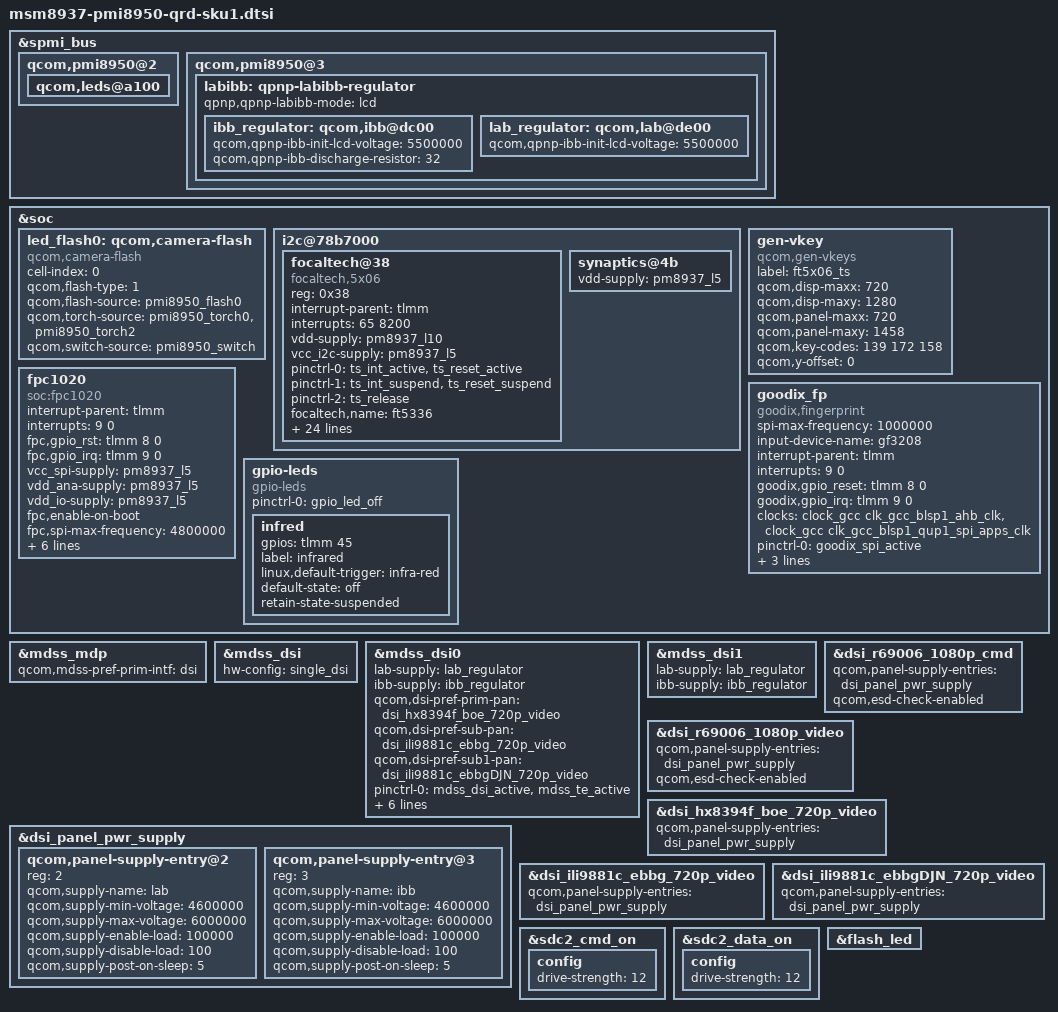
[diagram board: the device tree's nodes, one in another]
/*
 * Copyright (c) 2015-2016, The Linux Foundation. All rights reserved.
 *
 * This program is free software; you can redistribute it and/or modify
 * it under the terms of the GNU General Public License version 2 and
 * only version 2 as published by the Free Software Foundation.
 *
 * This program is distributed in the hope that it will be useful,
 * but WITHOUT ANY WARRANTY; without even the implied warranty of
 * MERCHANTABILITY or FITNESS FOR A PARTICULAR PURPOSE.  See the
 * GNU General Public License for more details.
 */

#include "msm-pmi8950.dtsi"
#include "msm8937-qrd.dtsi"
#include "msm8937-mdss-panels.dtsi"

&spmi_bus {
	qcom,pmi8950@2 {
		qcom,leds@a100 {
			//status = "okay";
			/*qcom,led_mpp_2 {
				label = "mpp";
				linux,name = "green";
				linux,default-trigger = "none";
				qcom,default-state = "off";
				qcom,max-current = <40>;
				qcom,current-setting = <5>;
				qcom,id = <6>;
				qcom,mode = "manual";
				qcom,source-sel = <1>;
				qcom,mode-ctrl = <0x60>;
			};*/
		};
	};
};

&soc {
	led_flash0: qcom,camera-flash {
		cell-index = <0>;
		compatible = "qcom,camera-flash";
		qcom,flash-type = <1>;
		qcom,flash-source = <&pmi8950_flash0>;
		qcom,torch-source = <&pmi8950_torch0 &pmi8950_torch2>;
		qcom,switch-source = <&pmi8950_switch>;
	};

	i2c@78b7000 {
		status = "ok";
		focaltech@38 {
			compatible = "focaltech,5x06"; //Our tp is FT5336
			reg = <0x38>; // 38
			interrupt-parent = <&tlmm>; // a7
			interrupts = <65 8200>;
			vdd-supply = <&pm8937_l10>; // cd
			vcc_i2c-supply = <&pm8937_l5>; //b6
			pinctrl-names = "pmx_ts_active", "pmx_ts_suspend", "pmx_ts_release";
			pinctrl-0 = <&ts_int_active &ts_reset_active>; // d0 d1
			pinctrl-1 = <&ts_int_suspend &ts_reset_suspend>; // d2 d3
			pinctrl-2 = <&ts_release>; // d4
			focaltech,name = "ft5336";
			focaltech,family-id = <0x36>;
			focaltech,reset-gpio = <&tlmm 64 0>; //a7
			focaltech,irq-gpio = <&tlmm 65 8200>; //a7
			focaltech,display-coords = <0 0 720 1280>;
			focaltech,panel-coords = <0 0 720 1280>;
			focaltech,virtual-key1 = <139 140 2000>; //menu
			focaltech,virtual-key2 = <172 360 2000>; //home
			focaltech,virtual-key3 = <158 580 2000>; //back
			//focaltech,fw-vkey-support;
			focaltech,button-map = <139 172 158>;			
			focaltech,no-force-update;
			focaltech,i2c-pull-up;
			focaltech,group-id = <1>;
			focaltech,hard-reset-delay-ms = <20>;
			focaltech,soft-reset-delay-ms = <200>;
			focaltech,num-max-touches = <10>;
			focaltech,fw-delay-aa-ms = <30>;
			focaltech,fw-delay-55-ms = <30>;
			focaltech,fw-upgrade-id1 = <121>;
			focaltech,fw-upgrade-id2 = <24>;
			focaltech,fw-delay-readid-ms = <10>;
			focaltech,fw-delay-era-flsh-ms = <2000>;
			focaltech,fw-auto-cal;
			focaltech,ignore-id-check;
			focaltech,resume-in-workqueue;
		};
		synaptics@4b {
			/*compatible = "synaptics,dsx";
			reg = <0x4b>;
			interrupt-parent = <&tlmm>;
			interrupts = <65 0x2008>;*/
			vdd-supply = <&pm8937_l5>;
			/*avdd-supply = <&pm8937_l10>;
			pinctrl-names = "pmx_ts_active","pmx_ts_suspend",
				"pmx_ts_release";
			pinctrl-0 = <&ts_int_active &ts_reset_active>;
			pinctrl-1 = <&ts_int_suspend &ts_reset_suspend>;
			pinctrl-2 = <&ts_release>;
			synaptics,display-coords = <0 0 1079 1919>;
			synaptics,panel-coords = <0 0 1079 1919>;
			synaptics,reset-gpio = <&tlmm 64 0x00>;
			synaptics,irq-gpio = <&tlmm 65 0x2008>;
			synaptics,disable-gpios;
			synaptics,button-map = <158 139 172>;
			synaptics,resume-in-workqueue;*/
			/* Underlying clocks used by secure touch */
			/*clock-names = "iface_clk", "core_clk";
			clocks = <&clock_gcc clk_gcc_blsp1_ahb_clk>,
				<&clock_gcc clk_gcc_blsp1_qup3_i2c_apps_clk>;*/
		};
	};

	gen-vkey {
			compatible = "qcom,gen-vkeys";
			label = "ft5x06_ts";
			qcom,disp-maxx = <720>; //<0x2d0>;
			qcom,disp-maxy = <1280>; //<0x500>;
			qcom,panel-maxx = <720>; //<0x2d0>;
			qcom,panel-maxy = <1458>; //<0x5b2>;
			qcom,key-codes = <139 172 158>; //<0x8b 0xac 0x9e>;
			qcom,y-offset = <0>; //<0x0>;
	};		

	//TODO Get correct gpios.
	fpc1020 {
		compatible = "soc:fpc1020";
		interrupt-parent = <&tlmm>;
		interrupts = <9 0>;
		fpc,gpio_rst = <&tlmm 8 0>;
		fpc,gpio_irq = <&tlmm 9 0>;
		vcc_spi-supply = <&pm8937_l5>;
		vdd_ana-supply = <&pm8937_l5>;
		vdd_io-supply = <&pm8937_l5>;
		fpc,enable-on-boot;
		/delete-property/
		fpc,enable-wakeup;
		fpc,spi-max-frequency = <4800000>;
		clock-names = "iface_clk", "core_clk";
		clocks = <&clock_gcc clk_gcc_blsp1_ahb_clk>,
				<&clock_gcc clk_gcc_blsp1_qup1_spi_apps_clk>;
		
		pinctrl-names = "fpc1020_spi_active", 
			"fpc1020_reset_reset", 
			"fpc1020_reset_active", 
			"fpc1020_irq_active";

		pinctrl-0 = <&fpc_spi_active>;
		pinctrl-1 = <&fpc_reset_reset>;
		pinctrl-2 = <&fpc_reset_active>;
		pinctrl-3 = <&fpc_irq_active>;
	};

	goodix_fp {
		compatible = "goodix,fingerprint";
		spi-max-frequency = <1000000>;
		input-device-name = "gf3208";
		interrupt-parent = <&tlmm>;
		interrupts = <9 0>;
		goodix,gpio_reset = <&tlmm 8 0>;
		goodix,gpio_irq = <&tlmm 9 0>;
		clock-names = "iface_clk", "core_clk";
		clocks = <&clock_gcc clk_gcc_blsp1_ahb_clk>,
				<&clock_gcc clk_gcc_blsp1_qup1_spi_apps_clk>;

		pinctrl-names = "goodix_spi_active", 
			"goodix_reset_reset", 
			"goodix_reset_active", 
			"goodix_irq_active";

		pinctrl-0 = <&goodix_spi_active>;
		pinctrl-1 = <&goodix_reset_reset>;
		pinctrl-2 = <&goodix_reset_active>;
		pinctrl-3 = <&goodix_irq_active>;
	};

	gpio-leds {
		compatible = "gpio-leds";
		status = "okay";
		pinctrl-names = "default";
		pinctrl-0 = <&gpio_led_off>;
		
		infred {
			gpios = <&tlmm 45 0>;
			label = "infrared";
			linux,default-trigger = "infra-red";
			default-state = "off";
			retain-state-suspended;
		};
	};

};

&mdss_mdp {
	qcom,mdss-pref-prim-intf = "dsi";
};

&mdss_dsi {
	hw-config = "single_dsi";
};

&mdss_dsi0 {
	lab-supply = <&lab_regulator>;
	ibb-supply = <&ibb_regulator>;
	
	qcom,dsi-pref-prim-pan = <&dsi_hx8394f_boe_720p_video>;
	qcom,dsi-pref-sub-pan = <&dsi_ili9881c_ebbg_720p_video>;
	qcom,dsi-pref-sub1-pan = <&dsi_ili9881c_ebbgDJN_720p_video>;

	pinctrl-names = "mdss_default", "mdss_sleep";
	pinctrl-0 = <&mdss_dsi_active &mdss_te_active>;
	pinctrl-1 = <&mdss_dsi_suspend &mdss_te_suspend>;

	qcom,platform-te-gpio = <&tlmm 24 0>;
	qcom,platform-reset-gpio = <&tlmm 60 0>;

	qcom,regulator-ldo-mode;
	qcom,platform-regulator-settings = [00 01 01 00 
					20 07 00];	
};

&mdss_dsi1 {
	//status = "disabled";
	lab-supply = <&lab_regulator>;
	ibb-supply = <&ibb_regulator>;
};

&labibb {
	status = "ok";
	qpnp,qpnp-labibb-mode = "lcd";
};

&ibb_regulator {
	qcom,qpnp-ibb-discharge-resistor = <32>;
};

&dsi_panel_pwr_supply {
	qcom,panel-supply-entry@2 {
		reg = <2>;
		qcom,supply-name = "lab";
		qcom,supply-min-voltage = <4600000>;
		qcom,supply-max-voltage = <6000000>;
		qcom,supply-enable-load = <100000>;
		qcom,supply-disable-load = <100>;
		qcom,supply-post-on-sleep = <5>;
	};

	qcom,panel-supply-entry@3 {
		reg = <3>;
		qcom,supply-name = "ibb";
		qcom,supply-min-voltage = <4600000>;
		qcom,supply-max-voltage = <6000000>;
		qcom,supply-enable-load = <100000>;
		qcom,supply-disable-load = <100>;
		qcom,supply-post-on-sleep = <5>;
	};
};

&dsi_r69006_1080p_cmd {
	qcom,panel-supply-entries = <&dsi_panel_pwr_supply>;
	qcom,esd-check-enabled;
};

&dsi_r69006_1080p_video {
	qcom,panel-supply-entries = <&dsi_panel_pwr_supply>;
	qcom,esd-check-enabled;
};

// Custom lcd panels
&dsi_hx8394f_boe_720p_video {
	qcom,panel-supply-entries = <&dsi_panel_pwr_supply>;
};

&dsi_ili9881c_ebbg_720p_video {
	qcom,panel-supply-entries = <&dsi_panel_pwr_supply>;
};

&dsi_ili9881c_ebbgDJN_720p_video {
	qcom,panel-supply-entries = <&dsi_panel_pwr_supply>;
};

&spmi_bus {
	qcom,pmi8950@3 {
		labibb: qpnp-labibb-regulator {
			ibb_regulator: qcom,ibb@dc00 {
				/delete-property/
					qcom,qpnp-ibb-use-default-voltage;
				qcom,qpnp-ibb-init-lcd-voltage = <5500000>;
			};

			lab_regulator: qcom,lab@de00 {
				/delete-property/
					qcom,qpnp-ibb-use-default-voltage;
				qcom,qpnp-ibb-init-lcd-voltage = <5500000>;
			};
		};
	};
};

&sdc2_cmd_on {
	config {
		drive-strength = <12>;
	};
};

&sdc2_data_on {
	config {
		drive-strength = <12>;
	};
};

&flash_led {
	/delete-node/ qcom,flash_1;
	/delete-node/ qcom,torch_1;
};
